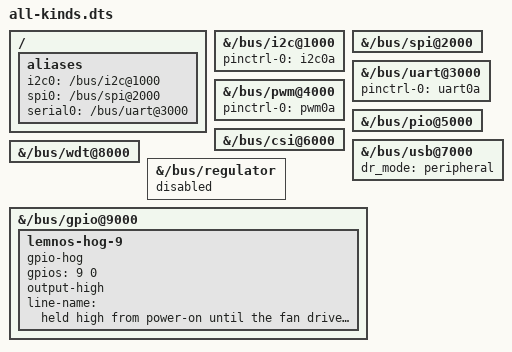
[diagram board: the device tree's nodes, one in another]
// Generated by `lemnos-ctl tree` from board "all-kinds". Do not edit: change the
// board file or the SoC map, and generate again.
// Every fragment says why it is here. Node paths are the base tree's.
/dts-v1/;
/plugin/;
/ {
	// i2c: an I2C bus (alias i2c0, the name "i2c-0") on GPIO0, GPIO1
	fragment@0 {
		target-path = "/bus/i2c@1000";
		__overlay__ {
			status = "okay";
			pinctrl-names = "default";
			pinctrl-0 = <&i2c0a>;
		};
	};
	// the runtime name comes out of alias i2c0
	fragment@1 {
		target-path = "/";
		__overlay__ {
			aliases { i2c0 = "/bus/i2c@1000"; };
		};
	};
	// spi: an SPI controller (alias spi0, the name "spidev0.0")
	fragment@2 {
		target-path = "/bus/spi@2000";
		__overlay__ {
			status = "okay";
		};
	};
	// the runtime name comes out of alias spi0
	fragment@3 {
		target-path = "/";
		__overlay__ {
			aliases { spi0 = "/bus/spi@2000"; };
		};
	};
	// uart: a serial port (alias serial0) on GPIO14, GPIO15
	fragment@4 {
		target-path = "/bus/uart@3000";
		__overlay__ {
			status = "okay";
			pinctrl-names = "default";
			pinctrl-0 = <&uart0a>;
		};
	};
	// the runtime name comes out of alias serial0
	fragment@5 {
		target-path = "/";
		__overlay__ {
			aliases { serial0 = "/bus/uart@3000"; };
		};
	};
	// pwm: a PWM block on GPIO18
	fragment@6 {
		target-path = "/bus/pwm@4000";
		__overlay__ {
			status = "okay";
			pinctrl-names = "default";
			pinctrl-0 = <&pwm0a>;
		};
	};
	// pio: the PIO block
	fragment@7 {
		target-path = "/bus/pio@5000";
		__overlay__ {
			status = "okay";
		};
	};
	// csi: a camera receiver
	fragment@8 {
		target-path = "/bus/csi@6000";
		__overlay__ {
			status = "okay";
		};
	};
	// usb-peripheral: a USB controller in peripheral mode
	fragment@9 {
		target-path = "/bus/usb@7000";
		__overlay__ {
			status = "okay";
			dr_mode = "peripheral";
		};
	};
	// watchdog: the hardware watchdog
	fragment@10 {
		target-path = "/bus/wdt@8000";
		__overlay__ {
			status = "okay";
		};
	};
	// disabled: base "b" /bus/regulator: a regulator on the line; the board gives gpio:gpio-test:9 to Lemnos
	fragment@11 {
		target-path = "/bus/regulator";
		__overlay__ {
			status = "disabled";
		};
	};
	// gpio-hog: gpio:gpio-test:9 is high from power-on, until the kernel takes the line
	fragment@12 {
		target-path = "/bus/gpio@9000";
		__overlay__ {
			lemnos-hog-9 { gpio-hog; gpios = <9 0>; output-high; line-name = "held high from power-on until the fan driver takes it"; };
		};
	};
};
